# COMPUTE_CLUSTER0_CTL_CFG_PI register map
Vendor: Texas Instruments
Peripheral module from a debugger description file (folder J7VCL).
Registers are 32-bit, read-write, reset 0x0 unless marked. A register's access mark holds for its fields unless they carry their own. Offsets are as the file gives them; lines under a group give offsets from that group; [hi:lo] are bit positions; {n}, {i} and the like mark numbered series; 'fields as' and 'values as' point back to an identical list; <NAME> marks a mode.

## COMPUTE_CLUSTER0_CTL_CFG_PI (part 1 of 2)
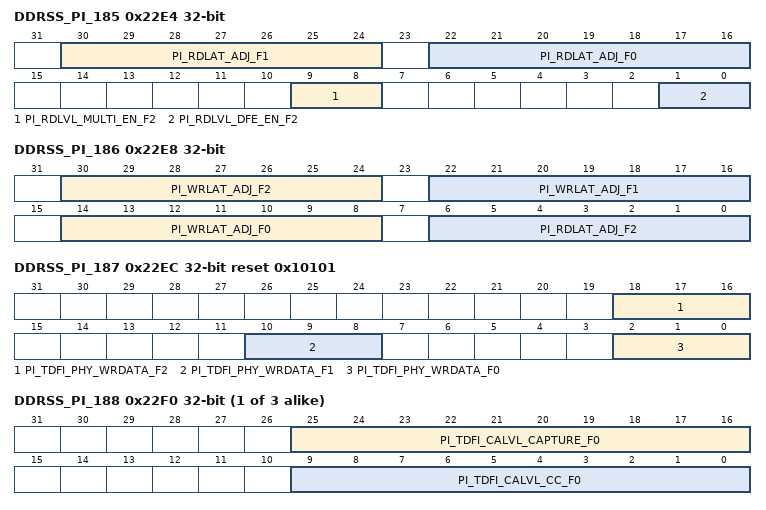
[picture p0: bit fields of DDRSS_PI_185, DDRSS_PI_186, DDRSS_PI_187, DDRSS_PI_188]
0x22E4 DDRSS_PI_185
  [30:24] PI_RDLAT_ADJ_F1 — Adjusts the relative timing between DFI read commands and the dfi_rddata_en signal for frequency set 1.
  [22:16] PI_RDLAT_ADJ_F0 — Adjusts the relative timing between DFI read commands and the dfi_rddata_en signal for frequency set 0.
  [9:8] PI_RDLVL_MULTI_EN_F2 — Enable Multi-pattern (from PI_RDLVL_PATTERN_START, total PI_RDLVL_PATTERN_NUM) for read training for frequency set 2.
  [1:0] PI_RDLVL_DFE_EN_F2 — Enable DFE (PATTERN 8,9) for read training for frequency set 2.
0x22E8 DDRSS_PI_186
  [30:24] PI_WRLAT_ADJ_F2 — Adjusts the relative timing in memory clocks between DFI write commands and the dfi_wrdata_en signal for frequency set 2.
  [22:16] PI_WRLAT_ADJ_F1 — Adjusts the relative timing in memory clocks between DFI write commands and the dfi_wrdata_en signal for frequency set 1.
  [14:8] PI_WRLAT_ADJ_F0 — Adjusts the relative timing in memory clocks between DFI write commands and the dfi_wrdata_en signal for frequency set 0.
  [6:0] PI_RDLAT_ADJ_F2 — Adjusts the relative timing between DFI read commands and the dfi_rddata_en signal for frequency set 2.
0x22EC DDRSS_PI_187 reset 0x10101
  [18:16] PI_TDFI_PHY_WRDATA_F2 — Defines the DFI tPHY_WRDATA timing parameter (in DFI PHY clocks) for frequency set 2, the maximum cycles between a dfi_wrdata_en assertion and a dfi_wrdata signal.
  [10:8] PI_TDFI_PHY_WRDATA_F1 — Defines the DFI tPHY_WRDATA timing parameter (in DFI PHY clocks) for frequency set 1, the maximum cycles between a dfi_wrdata_en assertion and a dfi_wrdata signal.
  [2:0] PI_TDFI_PHY_WRDATA_F0 — Defines the DFI tPHY_WRDATA timing parameter (in DFI PHY clocks) for frequency set 0, the maximum cycles between a dfi_wrdata_en assertion and a dfi_wrdata signal.
{0x2000+4i} DDRSS_PI_{i} (i=188..190)
  [25:16] PI_TDFI_CALVL_CAPTURE_F{i-188} — Defines the DFI tCALVL_CAPTURE timing parameter (in DFI clocks) for frequency set {i-188}, the minimum cycles between a calibration command and a dfi_calvl_capture pulse.
  [9:0] PI_TDFI_CALVL_CC_F{i-188} — Defines the DFI tCALVL_CC timing parameter (in DFI clocks) for frequency set {i-188}, the minimum cycles between calibration commands.
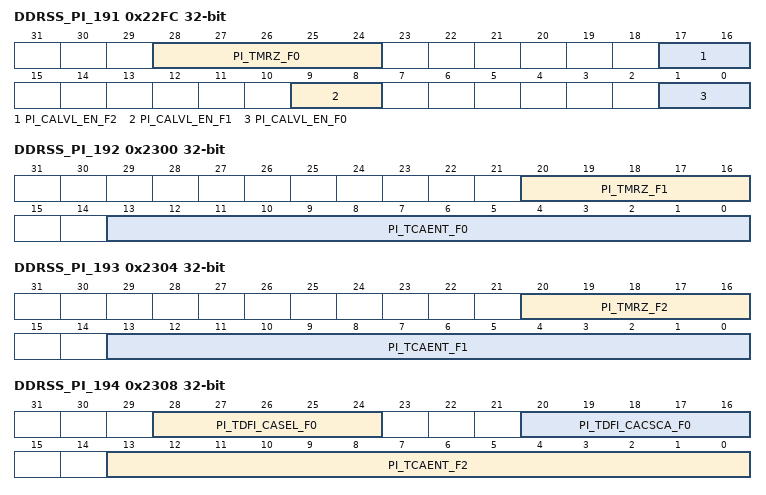
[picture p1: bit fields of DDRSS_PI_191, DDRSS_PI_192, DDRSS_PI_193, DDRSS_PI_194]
0x22FC DDRSS_PI_191
  [28:24] PI_TMRZ_F0 — Defines the delay between a MRW CA exit command and the DQ tristate in memory clocks for frequency set 0.
  [17:16] PI_CALVL_EN_F2 — Enable the PI CA training module.
  [9:8] PI_CALVL_EN_F1 — Enable the PI CA training module.
  [1:0] PI_CALVL_EN_F0 — Enable the PI CA training module.
0x2300 DDRSS_PI_192
  [20:16] PI_TMRZ_F1 — Defines the delay between a MRW CA exit command and the DQ tristate in memory clocks for frequency set 1.
  [13:0] PI_TCAENT_F0 — Defines the DRAM tCAENT term, in memory clocks for frequency set 0.
0x2304 DDRSS_PI_193
  [20:16] PI_TMRZ_F2 — Defines the delay between a MRW CA exit command and the DQ tristate in memory clocks for frequency set 2.
  [13:0] PI_TCAENT_F1 — Defines the DRAM tCAENT term, in memory clocks for frequency set 1.
0x2308 DDRSS_PI_194
  [28:24] PI_TDFI_CASEL_F0 — Defines the DFI tcalvl_ca_sel timing parameter, the width of dfi_calvl_ca_sel in PHY DFI clock cycles for frequency set 0.
  [20:16] PI_TDFI_CACSCA_F0 — Defines the DFI tcalvl_cs_ca timing parameter, the number of PHY DFI clocks from the assertion of dfi_calvl_ca_sel to the assertion of dfi_cs for frequency set 0.
  [13:0] PI_TCAENT_F2 — Defines the DRAM tCAENT term, in memory clocks for frequency set 2.
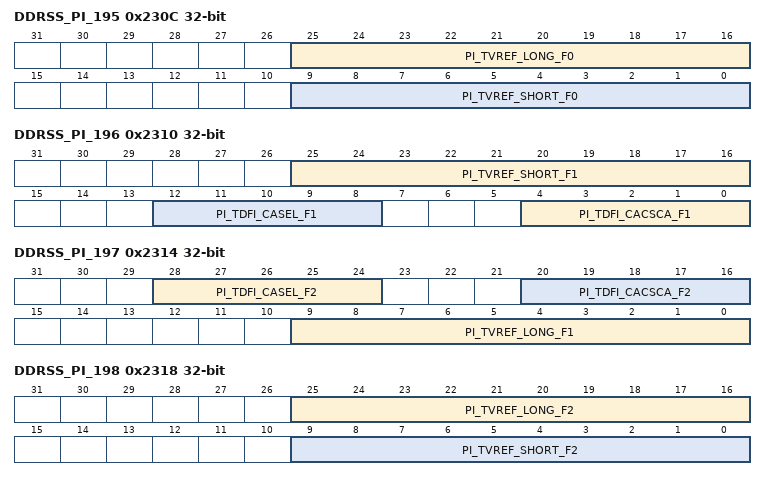
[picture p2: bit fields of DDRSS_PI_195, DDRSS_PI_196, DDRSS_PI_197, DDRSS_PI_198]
0x230C DDRSS_PI_195
  [25:16] PI_TVREF_LONG_F0 — Defines the delay in PI clock cycles between the dfi_calvl_strobe to the next command if the pi_calvl_vref_stepsize parameter gt 1 for frequency set 0.
  [9:0] PI_TVREF_SHORT_F0 — Defines the delay in PI clock cycles between the dfi_calvl_strobe to the next command if the pi_calvl_vref_stepsize parameter = 1 for frequency set 0.
0x2310 DDRSS_PI_196
  [25:16] PI_TVREF_SHORT_F1 — Defines the delay in PI clock cycles between the dfi_calvl_strobe to the next command if the pi_calvl_vref_stepsize parameter = 1 for frequency set 1.
  [12:8] PI_TDFI_CASEL_F1 — Defines the DFI tcalvl_ca_sel timing parameter, the width of dfi_calvl_ca_sel in PHY DFI clock cycles for frequency set 1.
  [4:0] PI_TDFI_CACSCA_F1 — Defines the DFI tcalvl_cs_ca timing parameter, the number of PHY DFI clocks from the assertion of dfi_calvl_ca_sel to the assertion of dfi_cs for frequency set 1.
0x2314 DDRSS_PI_197
  [28:24] PI_TDFI_CASEL_F2 — Defines the DFI tcalvl_ca_sel timing parameter, the width of dfi_calvl_ca_sel in PHY DFI clock cycles for frequency set 2.
  [20:16] PI_TDFI_CACSCA_F2 — Defines the DFI tcalvl_cs_ca timing parameter, the number of PHY DFI clocks from the assertion of dfi_calvl_ca_sel to the assertion of dfi_cs for frequency set 2.
  [9:0] PI_TVREF_LONG_F1 — Defines the delay in PI clock cycles between the dfi_calvl_strobe to the next command if the pi_calvl_vref_stepsize parameter gt 1 for frequency set 1.
0x2318 DDRSS_PI_198
  [25:16] PI_TVREF_LONG_F2 — Defines the delay in PI clock cycles between the dfi_calvl_strobe to the next command if the pi_calvl_vref_stepsize parameter gt 1 for frequency set 2.
  [9:0] PI_TVREF_SHORT_F2 — Defines the delay in PI clock cycles between the dfi_calvl_strobe to the next command if the pi_calvl_vref_stepsize parameter = 1 for frequency set 2.
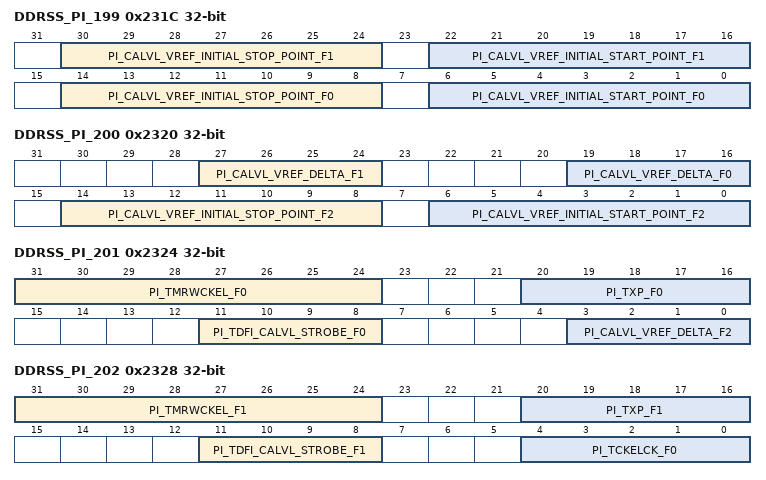
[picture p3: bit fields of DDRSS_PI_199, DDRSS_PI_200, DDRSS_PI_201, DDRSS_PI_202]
0x231C DDRSS_PI_199
  [30:24] PI_CALVL_VREF_INITIAL_STOP_POINT_F1 — The end point of initial training for the Vref(ca) training for frequency set 1 { vrefca_range, vref_ca_setting
  [22:16] PI_CALVL_VREF_INITIAL_START_POINT_F1 — The start point of initial training for the Vref(ca) training for frequency set 1 { vrefca_range, vref_ca_setting
  [14:8] PI_CALVL_VREF_INITIAL_STOP_POINT_F0 — The end point of initial training for the Vref(ca) training for frequency set 0 { vrefca_range, vref_ca_setting
  [6:0] PI_CALVL_VREF_INITIAL_START_POINT_F0 — The start point of initial training for the Vref(ca) training for frequency set 0 { vrefca_range, vref_ca_setting
0x2320 DDRSS_PI_200
  [27:24] PI_CALVL_VREF_DELTA_F1 — The delta fro the current CA vref for non-initial CA training for frequency set 1.
  [19:16] PI_CALVL_VREF_DELTA_F0 — The delta fro the current CA vref for non-initial CA training for frequency set 0.
  [14:8] PI_CALVL_VREF_INITIAL_STOP_POINT_F2 — The end point of initial training for the Vref(ca) training for frequency set 2 { vrefca_range, vref_ca_setting
  [6:0] PI_CALVL_VREF_INITIAL_START_POINT_F2 — The start point of initial training for the Vref(ca) training for frequency set 2 { vrefca_range, vref_ca_setting
0x2324 DDRSS_PI_201
  [31:24] PI_TMRWCKEL_F0 — Valid Clock and CS Requirement before CKE deassert after MRW Command for frequency set 0.
  [20:16] PI_TXP_F0 — CKE assert to next valid command delay for frequency set 0.
  [11:8] PI_TDFI_CALVL_STROBE_F0 — Minimum number of DFI PHY clocks from dfi_calvl_data to dfi_calvl_strobe mode for frequency set 0.
  [3:0] PI_CALVL_VREF_DELTA_F2 — The delta fro the current CA vref for non-initial CA training for frequency set 2.
0x2328 DDRSS_PI_202
  [31:24] PI_TMRWCKEL_F1 — Valid Clock and CS Requirement before CKE deassert after MRW Command for frequency set 1.
  [20:16] PI_TXP_F1 — CKE assert to next valid command delay for frequency set 1.
  [11:8] PI_TDFI_CALVL_STROBE_F1 — Minimum number of DFI PHY clocks from dfi_calvl_data to dfi_calvl_strobe mode for frequency set 1.
  [4:0] PI_TCKELCK_F0 — Valid Clock Requirement after CKE deassert for frequency set 0.
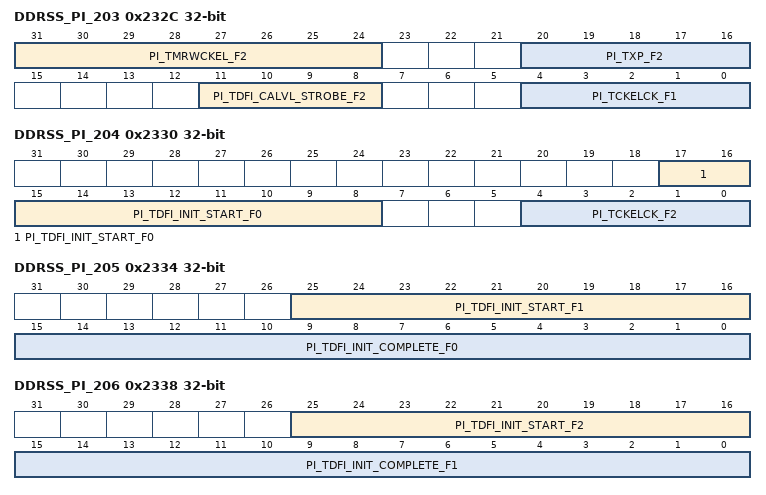
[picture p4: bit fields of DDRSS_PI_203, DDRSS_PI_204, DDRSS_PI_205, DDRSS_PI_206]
0x232C DDRSS_PI_203
  [31:24] PI_TMRWCKEL_F2 — Valid Clock and CS Requirement before CKE deassert after MRW Command for frequency set 2.
  [20:16] PI_TXP_F2 — CKE assert to next valid command delay for frequency set 2.
  [11:8] PI_TDFI_CALVL_STROBE_F2 — Minimum number of DFI PHY clocks from dfi_calvl_data to dfi_calvl_strobe mode for frequency set 2.
  [4:0] PI_TCKELCK_F1 — Valid Clock Requirement after CKE deassert for frequency set 1.
0x2330 DDRSS_PI_204
  [17:8] PI_TDFI_INIT_START_F0 — Defines the DFI tINIT_START timing parameter (in DFI clocks) for frequency set 0, the maximum number of cycles between a dfi_init_start assertion and a dfi_init_complete de-assertion from the PHY.
  [4:0] PI_TCKELCK_F2 — Valid Clock Requirement after CKE deassert for frequency set 2.
0x2334 DDRSS_PI_205
  [25:16] PI_TDFI_INIT_START_F1 — Defines the DFI tINIT_START timing parameter (in DFI clocks) for frequency set 1, the maximum number of cycles between a dfi_init_start assertion and a dfi_init_complete de-assertion from the PHY.
  [15:0] PI_TDFI_INIT_COMPLETE_F0 — Defines the DFI tINIT_COMPLETE timing parameter (in DFI clocks) for frequency set 0, the maximum cycles between a dfi_init_start de-assertion and a dfi_init_complete assertion from the PHY.
0x2338 DDRSS_PI_206
  [25:16] PI_TDFI_INIT_START_F2 — Defines the DFI tINIT_START timing parameter (in DFI clocks) for frequency set 2, the maximum number of cycles between a dfi_init_start assertion and a dfi_init_complete de-assertion from the PHY.
  [15:0] PI_TDFI_INIT_COMPLETE_F1 — Defines the DFI tINIT_COMPLETE timing parameter (in DFI clocks) for frequency set 1, the maximum cycles between a dfi_init_start de-assertion and a dfi_init_complete assertion from the PHY.
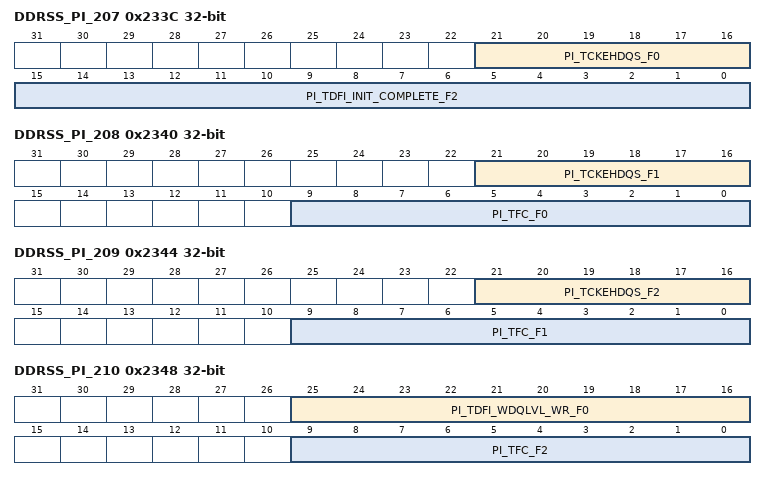
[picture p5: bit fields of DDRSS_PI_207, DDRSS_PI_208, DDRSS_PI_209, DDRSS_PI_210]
0x233C DDRSS_PI_207
  [21:16] PI_TCKEHDQS_F0 — The DRAM timing tCKEHDQS, minimum delay from CKE high to strobe high impedance for frequency set 0.
  [15:0] PI_TDFI_INIT_COMPLETE_F2 — Defines the DFI tINIT_COMPLETE timing parameter (in DFI clocks) for frequency set 2, the maximum cycles between a dfi_init_start de-assertion and a dfi_init_complete assertion from the PHY.
0x2340 DDRSS_PI_208
  [21:16] PI_TCKEHDQS_F1 — The DRAM timing tCKEHDQS, minimum delay from CKE high to strobe high impedance for frequency set 1.
  [9:0] PI_TFC_F0 — The delay in PHY clock cycles from setting MR13.OP7 to any valid command for frequency set 0.
0x2344 DDRSS_PI_209
  [21:16] PI_TCKEHDQS_F2 — The DRAM timing tCKEHDQS, minimum delay from CKE high to strobe high impedance for frequency set 2.
  [9:0] PI_TFC_F1 — The delay in PHY clock cycles from setting MR13.OP7 to any valid command for frequency set 1.
0x2348 DDRSS_PI_210
  [25:16] PI_TDFI_WDQLVL_WR_F0 — Switch time from write to read for frequency set 0.
  [9:0] PI_TFC_F2 — The delay in PHY clock cycles from setting MR13.OP7 to any valid command for frequency set 2.
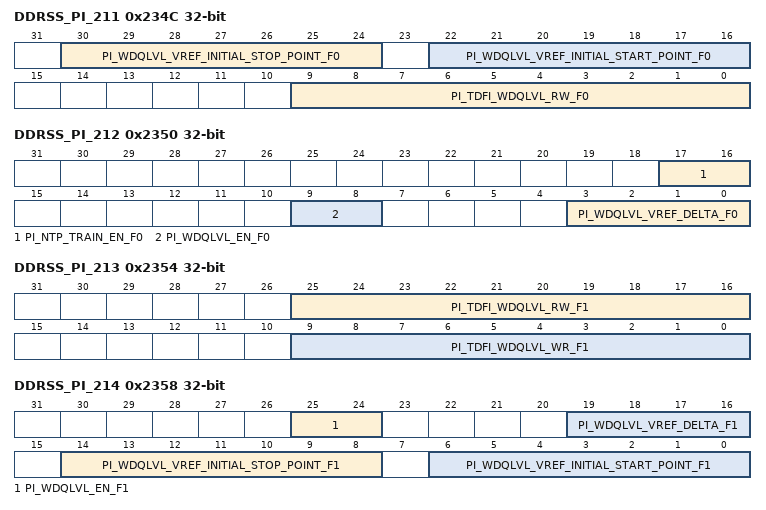
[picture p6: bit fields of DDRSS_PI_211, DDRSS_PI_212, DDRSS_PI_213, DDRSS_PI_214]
0x234C DDRSS_PI_211
  [30:24] PI_WDQLVL_VREF_INITIAL_STOP_POINT_F0 — Write DQ training vref initial training stop value for frequency set 0.
  [22:16] PI_WDQLVL_VREF_INITIAL_START_POINT_F0 — Write DQ training vref initial training start value for frequency set 0.
  [9:0] PI_TDFI_WDQLVL_RW_F0 — Switch time from read to write for frequency set 0.
0x2350 DDRSS_PI_212
  [17:16] PI_NTP_TRAIN_EN_F0 — Indicates whether the no topology WDQ training is enabled.
  [9:8] PI_WDQLVL_EN_F0 — Indicates if Write DQ leveling is enabled for frequency set 0.
  [3:0] PI_WDQLVL_VREF_DELTA_F0 — The delta from the current Write DQ vref adjustment for non-initial wdq training for frequency set 0.
0x2354 DDRSS_PI_213
  [25:16] PI_TDFI_WDQLVL_RW_F1 — Switch time from read to write for frequency set 1.
  [9:0] PI_TDFI_WDQLVL_WR_F1 — Switch time from write to read for frequency set 1.
0x2358 DDRSS_PI_214
  [25:24] PI_WDQLVL_EN_F1 — Indicates if Write DQ leveling is enabled for frequency set 1.
  [19:16] PI_WDQLVL_VREF_DELTA_F1 — The delta from the current Write DQ vref adjustment for non-initial wdq training for frequency set 1.
  [14:8] PI_WDQLVL_VREF_INITIAL_STOP_POINT_F1 — Write DQ training vref initial training stop value for frequency set 1.
  [6:0] PI_WDQLVL_VREF_INITIAL_START_POINT_F1 — Write DQ training vref initial training start value for frequency set 1.
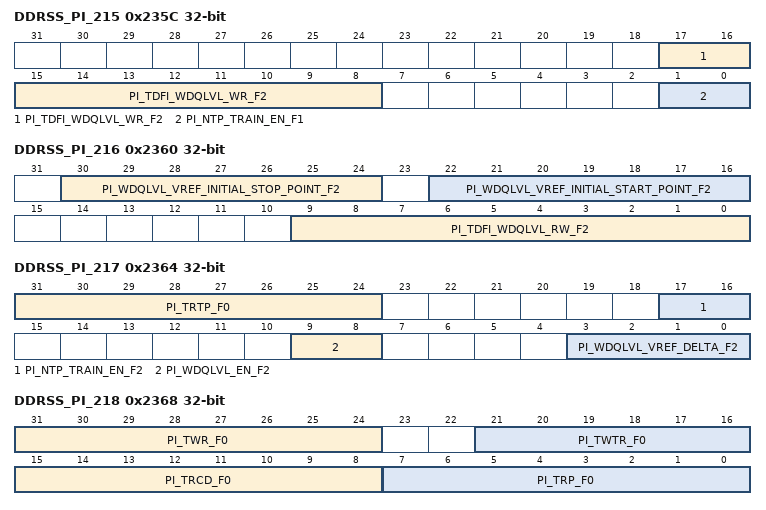
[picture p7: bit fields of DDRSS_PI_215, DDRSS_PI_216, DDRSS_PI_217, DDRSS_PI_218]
0x235C DDRSS_PI_215
  [17:8] PI_TDFI_WDQLVL_WR_F2 — Switch time from write to read for frequency set 2.
  [1:0] PI_NTP_TRAIN_EN_F1 — Indicates whether the no topology WDQ training is enabled.
0x2360 DDRSS_PI_216
  [30:24] PI_WDQLVL_VREF_INITIAL_STOP_POINT_F2 — Write DQ training vref initial training stop value for frequency set 2.
  [22:16] PI_WDQLVL_VREF_INITIAL_START_POINT_F2 — Write DQ training vref initial training start value for frequency set 2.
  [9:0] PI_TDFI_WDQLVL_RW_F2 — Switch time from read to write for frequency set 2.
0x2364 DDRSS_PI_217
  [31:24] PI_TRTP_F0 — DRAM tRTP value in cycles for frequency set 0.
  [17:16] PI_NTP_TRAIN_EN_F2 — Indicates whether the no topology WDQ training is enabled.
  [9:8] PI_WDQLVL_EN_F2 — Indicates if Write DQ leveling is enabled for frequency set 2.
  [3:0] PI_WDQLVL_VREF_DELTA_F2 — The delta from the current Write DQ vref adjustment for non-initial wdq training for frequency set 2.
0x2368 DDRSS_PI_218
  [31:24] PI_TWR_F0 — DRAM tWR value in cycles for frequency set 0.
  [21:16] PI_TWTR_F0 — DRAM tWTR value in cycles for frequency set 0.
  [15:8] PI_TRCD_F0 — DRAM tRCD value in cycles for frequency set 0.
  [7:0] PI_TRP_F0 — DRAM tRP value in cycles for frequency set 0.
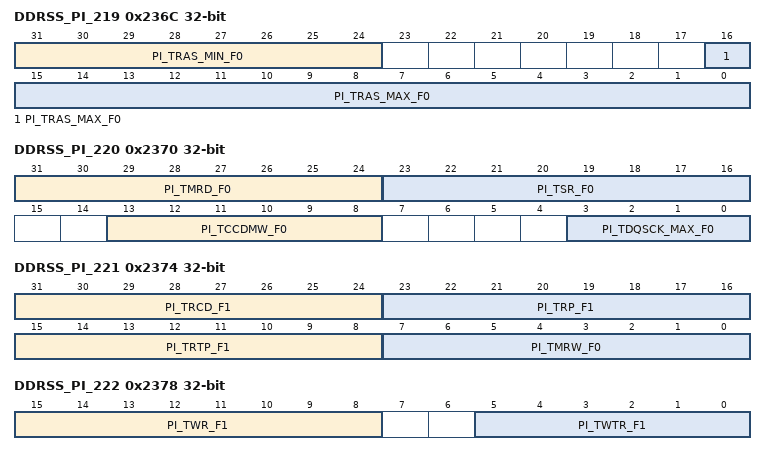
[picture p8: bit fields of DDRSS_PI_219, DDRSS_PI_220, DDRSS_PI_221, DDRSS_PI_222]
0x236C DDRSS_PI_219
  [31:24] PI_TRAS_MIN_F0 — DRAM tRAS_MIN value in cycles for frequency set 0.
  [16:0] PI_TRAS_MAX_F0 — DRAM tRAS_MAX value in cycles for frequency set 0.
0x2370 DDRSS_PI_220
  [31:24] PI_TMRD_F0 — DRAM tMRD value in cycles for frequency set 0.
  [23:16] PI_TSR_F0 — Min cycles from sref entry to sref exit for frequency set 0.
  [13:8] PI_TCCDMW_F0 — LPDDR4 DRAM tCCDMW in cycles for frequency set 0.
  [3:0] PI_TDQSCK_MAX_F0 — Additional delay needed for tDQSCK for frequency set 0.
0x2374 DDRSS_PI_221
  [31:24] PI_TRCD_F1 — DRAM tRCD value in cycles for frequency set 1.
  [23:16] PI_TRP_F1 — DRAM tRP value in cycles for frequency set 1.
  [15:8] PI_TRTP_F1 — DRAM tRTP value in cycles for frequency set 1.
  [7:0] PI_TMRW_F0 — DRAM tMRW value in cycles for frequency set 0.
0x2378 DDRSS_PI_222
  [15:8] PI_TWR_F1 — DRAM tWR value in cycles for frequency set 1.
  [5:0] PI_TWTR_F1 — DRAM tWTR value in cycles for frequency set 1.
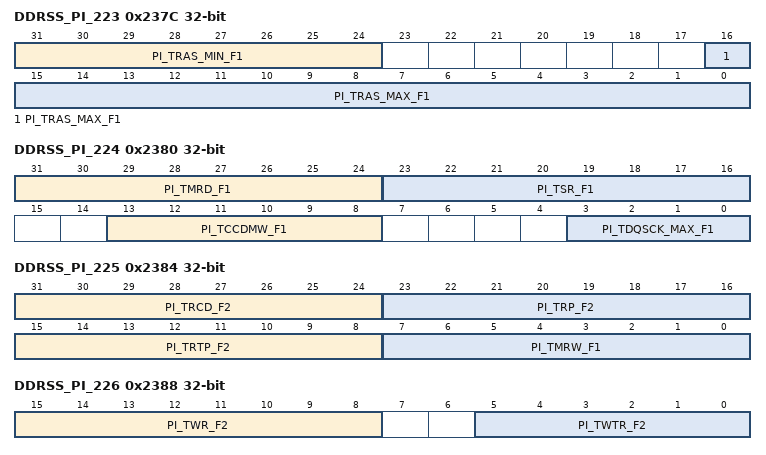
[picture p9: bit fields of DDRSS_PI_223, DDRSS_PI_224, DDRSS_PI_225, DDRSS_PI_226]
0x237C DDRSS_PI_223
  [31:24] PI_TRAS_MIN_F1 — DRAM tRAS_MIN value in cycles for frequency set 1.
  [16:0] PI_TRAS_MAX_F1 — DRAM tRAS_MAX value in cycles for frequency set 1.
0x2380 DDRSS_PI_224
  [31:24] PI_TMRD_F1 — DRAM tMRD value in cycles for frequency set 1.
  [23:16] PI_TSR_F1 — Min cycles from sref entry to sref exit for frequency set 1.
  [13:8] PI_TCCDMW_F1 — LPDDR4 DRAM tCCDMW in cycles for frequency set 1.
  [3:0] PI_TDQSCK_MAX_F1 — Additional delay needed for tDQSCK for frequency set 1.
0x2384 DDRSS_PI_225
  [31:24] PI_TRCD_F2 — DRAM tRCD value in cycles for frequency set 2.
  [23:16] PI_TRP_F2 — DRAM tRP value in cycles for frequency set 2.
  [15:8] PI_TRTP_F2 — DRAM tRTP value in cycles for frequency set 2.
  [7:0] PI_TMRW_F1 — DRAM tMRW value in cycles for frequency set 1.
0x2388 DDRSS_PI_226
  [15:8] PI_TWR_F2 — DRAM tWR value in cycles for frequency set 2.
  [5:0] PI_TWTR_F2 — DRAM tWTR value in cycles for frequency set 2.
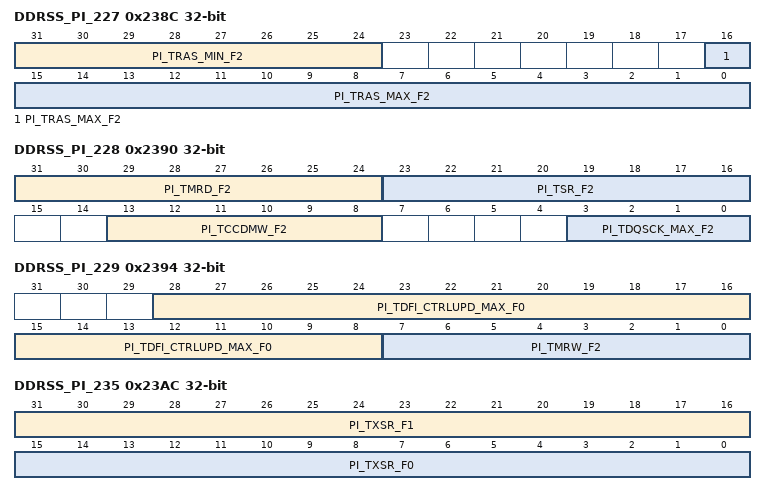
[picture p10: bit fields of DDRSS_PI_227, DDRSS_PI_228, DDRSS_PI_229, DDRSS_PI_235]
0x238C DDRSS_PI_227
  [31:24] PI_TRAS_MIN_F2 — DRAM tRAS_MIN value in cycles for frequency set 2.
  [16:0] PI_TRAS_MAX_F2 — DRAM tRAS_MAX value in cycles for frequency set 2.
0x2390 DDRSS_PI_228
  [31:24] PI_TMRD_F2 — DRAM tMRD value in cycles for frequency set 2.
  [23:16] PI_TSR_F2 — Min cycles from sref entry to sref exit for frequency set 2.
  [13:8] PI_TCCDMW_F2 — LPDDR4 DRAM tCCDMW in cycles for frequency set 2.
  [3:0] PI_TDQSCK_MAX_F2 — Additional delay needed for tDQSCK for frequency set 2.
0x2394 DDRSS_PI_229
  [28:8] PI_TDFI_CTRLUPD_MAX_F0 — Defines the DFI tCTRLUPD_MAX timing parameter (in DFI clocks) for frequency set 0, the maximum cycles that dfi_ctrlupd_req can be asserted.
  [7:0] PI_TMRW_F2 — DRAM tMRW value in cycles for frequency set 2.
0x2398 DDRSS_PI_230
  [31:0] PI_TDFI_CTRLUPD_INTERVAL_F0 — Defines the DFI tCTRLUPD_INTERVAL timing parameter (in DFI clocks) for frequency set 0, the maximum cycles between dfi_ctrlupd_req assertions.
0x239C DDRSS_PI_231
  [20:0] PI_TDFI_CTRLUPD_MAX_F1 — Defines the DFI tCTRLUPD_MAX timing parameter (in DFI clocks) for frequency set 1, the maximum cycles that dfi_ctrlupd_req can be asserted.
0x23A0 DDRSS_PI_232
  [31:0] PI_TDFI_CTRLUPD_INTERVAL_F1 — Defines the DFI tCTRLUPD_INTERVAL timing parameter (in DFI clocks) for frequency set 1, the maximum cycles between dfi_ctrlupd_req assertions.
0x23A4 DDRSS_PI_233
  [20:0] PI_TDFI_CTRLUPD_MAX_F2 — Defines the DFI tCTRLUPD_MAX timing parameter (in DFI clocks) for frequency set 2, the maximum cycles that dfi_ctrlupd_req can be asserted.
0x23A8 DDRSS_PI_234
  [31:0] PI_TDFI_CTRLUPD_INTERVAL_F2 — Defines the DFI tCTRLUPD_INTERVAL timing parameter (in DFI clocks) for frequency set 2, the maximum cycles between dfi_ctrlupd_req assertions.
0x23AC DDRSS_PI_235
  [31:16] PI_TXSR_F1 — DRAM TXSR value for frequency set 1 in cycles.
  [15:0] PI_TXSR_F0 — DRAM TXSR value for frequency set 0 in cycles.
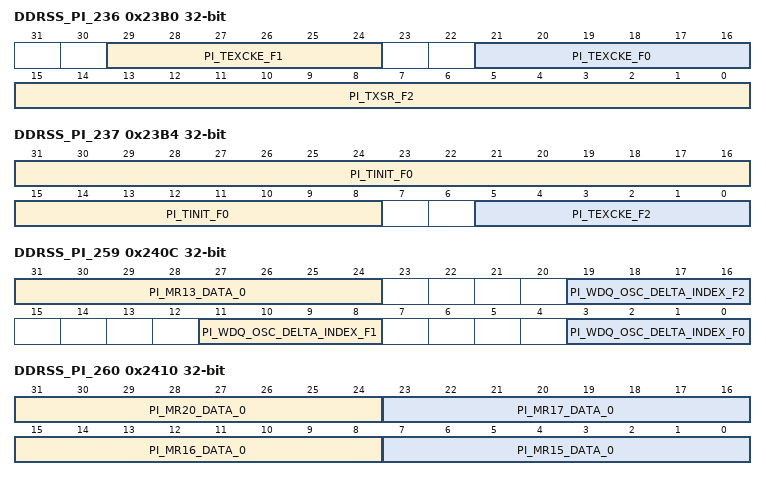
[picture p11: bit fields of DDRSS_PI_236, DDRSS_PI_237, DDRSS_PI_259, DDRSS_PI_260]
0x23B0 DDRSS_PI_236
  [29:24] PI_TEXCKE_F1 — DRAM CKE low after SREF command timing for frequency set 1.
  [21:16] PI_TEXCKE_F0 — DRAM CKE low after SREF command timing for frequency set 0.
  [15:0] PI_TXSR_F2 — DRAM TXSR value for frequency set 2 in cycles.
0x23B4 DDRSS_PI_237
  [31:8] PI_TINIT_F0 — DRAM tINIT value for frequency set 0 in cycles.
  [5:0] PI_TEXCKE_F2 — DRAM CKE low after SREF command timing for frequency set 2.
{0x2000+4i} DDRSS_PI_{i} (i=238..240)
  [23:0] PI_TINIT{i-235}_F0 — DRAM tINIT{i-235} value for frequency set 0 in cycles.
0x23C4 DDRSS_PI_241
  [15:0] PI_TXSNR_F0 — DRAM tXSNR value for frequency set 0 in cycles.
0x23C8 DDRSS_PI_242
  [23:0] PI_TINIT_F1 — DRAM tINIT value for frequency set 1 in cycles.
{0x2000+4i} DDRSS_PI_{i} (i=243..245)
  [23:0] PI_TINIT{i-240}_F1 — DRAM tINIT{i-240} value for frequency set 1 in cycles.
0x23D8 DDRSS_PI_246
  [15:0] PI_TXSNR_F1 — DRAM tXSNR value for frequency set 1 in cycles.
0x23DC DDRSS_PI_247
  [23:0] PI_TINIT_F2 — DRAM tINIT value for frequency set 2 in cycles.
{0x2000+4i} DDRSS_PI_{i} (i=248..250)
  [23:0] PI_TINIT{i-245}_F2 — DRAM tINIT{i-245} value for frequency set 2 in cycles.
0x23EC DDRSS_PI_251
  [15:0] PI_TXSNR_F2 — DRAM tXSNR value for frequency set 2 in cycles.
0x23F0 DDRSS_PI_252
  [27:16] PI_TZQCAL_F0 — Holds the DRAM ZQCAL value for frequency set 0 in cycles.
0x23F4 DDRSS_PI_253
  [6:0] PI_TZQLAT_F0 — Holds the DRAM ZQLAT value for frequency set 0 in cycles.
0x23F8 DDRSS_PI_254
  [27:16] PI_TZQCAL_F1 — Holds the DRAM ZQCAL value for frequency set 1 in cycles.
0x23FC DDRSS_PI_255
  [6:0] PI_TZQLAT_F1 — Holds the DRAM ZQLAT value for frequency set 1 in cycles.
0x2400 DDRSS_PI_256
  [27:16] PI_TZQCAL_F2 — Holds the DRAM ZQCAL value for frequency set 2 in cycles.
0x2404 DDRSS_PI_257
  [6:0] PI_TZQLAT_F2 — Holds the DRAM ZQLAT value for frequency set 2 in cycles.
0x2408 DDRSS_PI_258 (reset mask 0xFFF0FFF)
0x240C DDRSS_PI_259
  [31:24] PI_MR13_DATA_0 — Data to program into memory mode register 13 for chip select 0.
  [19:16] PI_WDQ_OSC_DELTA_INDEX_F2 — WDQ DQS delay delta index for OSC triggered periodic training for frequency set 2.
  [11:8] PI_WDQ_OSC_DELTA_INDEX_F1 — WDQ DQS delay delta index for OSC triggered periodic training for frequency set 1.
  [3:0] PI_WDQ_OSC_DELTA_INDEX_F0 — WDQ DQS delay delta index for OSC triggered periodic training for frequency set 0.
0x2410 DDRSS_PI_260
  [31:24] PI_MR20_DATA_0 — Data to program into memory mode register 20 for chip select 0.
  [23:16] PI_MR17_DATA_0 — Data to program into memory mode register 17 for chip select 0.
  [15:8] PI_MR16_DATA_0 — Data to program into memory mode register 16 for chip select 0.
  [7:0] PI_MR15_DATA_0 — Data to program into memory mode register 15 for chip select 0.
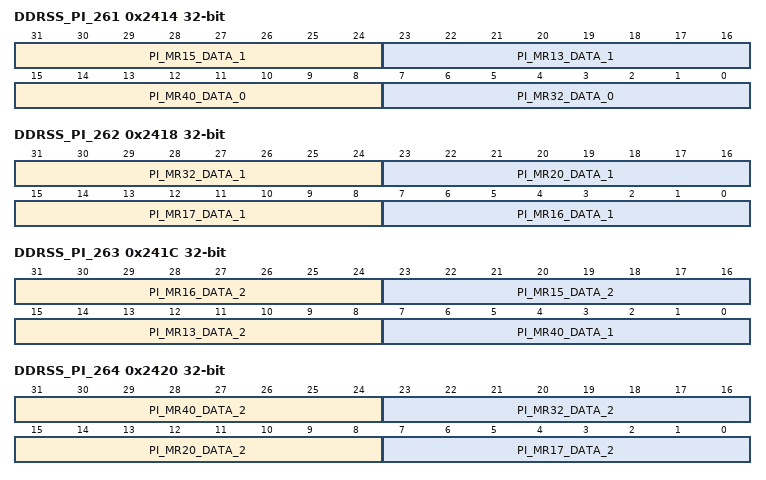
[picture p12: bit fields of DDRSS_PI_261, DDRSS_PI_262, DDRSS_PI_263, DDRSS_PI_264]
0x2414 DDRSS_PI_261
  [31:24] PI_MR15_DATA_1 — Data to program into memory mode register 15 for chip select 1.
  [23:16] PI_MR13_DATA_1 — Data to program into memory mode register 13 for chip select 1.
  [15:8] PI_MR40_DATA_0 — Data to program into memory mode register 40 for chip select 0.
  [7:0] PI_MR32_DATA_0 — Data to program into memory mode register 32 for chip select 0.
0x2418 DDRSS_PI_262
  [31:24] PI_MR32_DATA_1 — Data to program into memory mode register 32 for chip select 1.
  [23:16] PI_MR20_DATA_1 — Data to program into memory mode register 20 for chip select 1.
  [15:8] PI_MR17_DATA_1 — Data to program into memory mode register 17 for chip select 1.
  [7:0] PI_MR16_DATA_1 — Data to program into memory mode register 16 for chip select 1.
0x241C DDRSS_PI_263
  [31:24] PI_MR16_DATA_2 — Data to program into memory mode register 16 for chip select 2.
  [23:16] PI_MR15_DATA_2 — Data to program into memory mode register 15 for chip select 2.
  [15:8] PI_MR13_DATA_2 — Data to program into memory mode register 13 for chip select 2.
  [7:0] PI_MR40_DATA_1 — Data to program into memory mode register 40 for chip select 1.
0x2420 DDRSS_PI_264
  [31:24] PI_MR40_DATA_2 — Data to program into memory mode register 40 for chip select 2.
  [23:16] PI_MR32_DATA_2 — Data to program into memory mode register 32 for chip select 2.
  [15:8] PI_MR20_DATA_2 — Data to program into memory mode register 20 for chip select 2.
  [7:0] PI_MR17_DATA_2 — Data to program into memory mode register 17 for chip select 2.
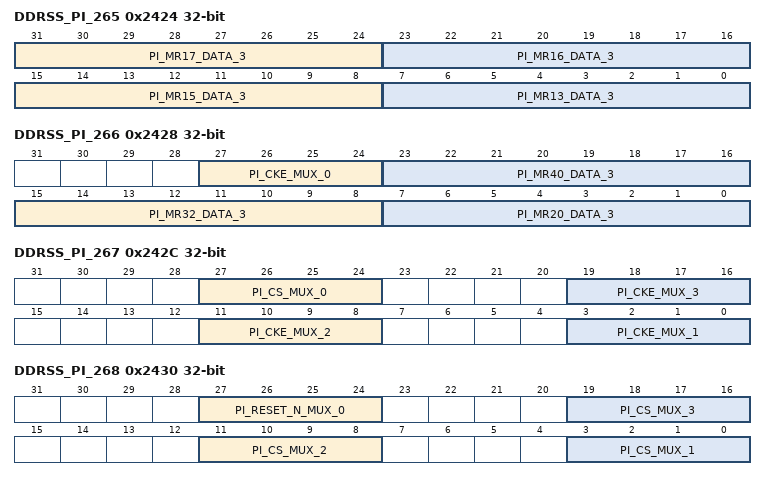
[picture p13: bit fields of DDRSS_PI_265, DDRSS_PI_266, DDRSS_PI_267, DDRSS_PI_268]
0x2424 DDRSS_PI_265
  [31:24] PI_MR17_DATA_3 — Data to program into memory mode register 17 for chip select 3.
  [23:16] PI_MR16_DATA_3 — Data to program into memory mode register 16 for chip select 3.
  [15:8] PI_MR15_DATA_3 — Data to program into memory mode register 15 for chip select 3.
  [7:0] PI_MR13_DATA_3 — Data to program into memory mode register 13 for chip select 3.
0x2428 DDRSS_PI_266
  [27:24] PI_CKE_MUX_0 — Command pin CKE_0 mux selector
  [23:16] PI_MR40_DATA_3 — Data to program into memory mode register 40 for chip select 3.
  [15:8] PI_MR32_DATA_3 — Data to program into memory mode register 32 for chip select 3.
  [7:0] PI_MR20_DATA_3 — Data to program into memory mode register 20 for chip select 3.
0x242C DDRSS_PI_267
  [27:24] PI_CS_MUX_0 — Command pin CS_0 mux selector
  [19:16] PI_CKE_MUX_3 — Command pin CKE_3 mux selector
  [11:8] PI_CKE_MUX_2 — Command pin CKE_2 mux selector
  [3:0] PI_CKE_MUX_1 — Command pin CKE_1 mux selector
0x2430 DDRSS_PI_268
  [27:24] PI_RESET_N_MUX_0 — Command pin RESET_N_0 mux selector
  [19:16] PI_CS_MUX_3 — Command pin CS_3 mux selector
  [11:8] PI_CS_MUX_2 — Command pin CS_2 mux selector
  [3:0] PI_CS_MUX_1 — Command pin CS_1 mux selector
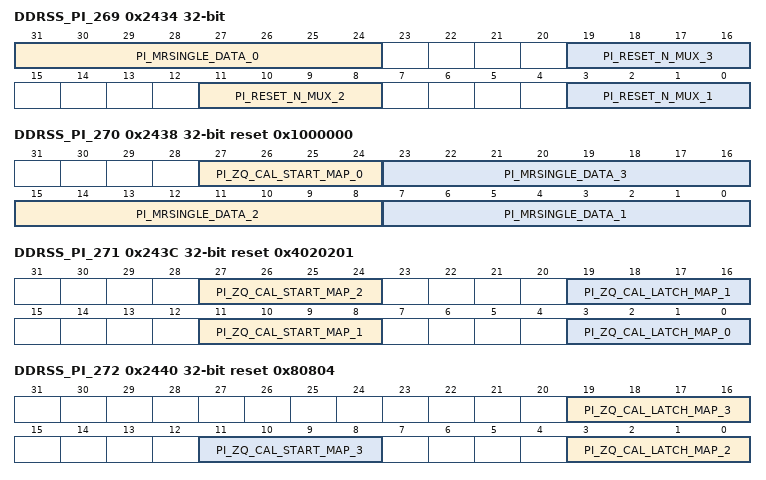
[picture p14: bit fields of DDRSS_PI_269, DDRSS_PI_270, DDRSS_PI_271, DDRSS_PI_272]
0x2434 DDRSS_PI_269
  [31:24] PI_MRSINGLE_DATA_0 — Data to program into memory mode register single write to chip select 0.
  [19:16] PI_RESET_N_MUX_3 — Command pin RESET_N_3 mux selector
  [11:8] PI_RESET_N_MUX_2 — Command pin RESET_N_2 mux selector
  [3:0] PI_RESET_N_MUX_1 — Command pin RESET_N_1 mux selector
0x2438 DDRSS_PI_270 reset 0x1000000
  [27:24] PI_ZQ_CAL_START_MAP_0 — Defines which chip select(s) will receive ZQ calibration start commands simultaneously on iteration 0 of the ZQ START initialization and periodic command sequences.
  [23:16] PI_MRSINGLE_DATA_3 — Data to program into memory mode register single write to chip select 3.
  [15:8] PI_MRSINGLE_DATA_2 — Data to program into memory mode register single write to chip select 2.
  [7:0] PI_MRSINGLE_DATA_1 — Data to program into memory mode register single write to chip select 1.
0x243C DDRSS_PI_271 reset 0x4020201
  [27:24] PI_ZQ_CAL_START_MAP_2 — Defines which chip select(s) will receive ZQ calibration start commands simultaneously on iteration 2 of the ZQ START initialization and periodic command sequences.
  [19:16] PI_ZQ_CAL_LATCH_MAP_1 — Defines which chip select(s) will receive ZQ calibration latch commands simultaneously on iteration 1 of the ZQ LATCH initialization and periodic command sequences.
  [11:8] PI_ZQ_CAL_START_MAP_1 — Defines which chip select(s) will receive ZQ calibration start commands simultaneously on iteration 1 of the ZQ START initialization and periodic command sequences.
  [3:0] PI_ZQ_CAL_LATCH_MAP_0 — Defines which chip select(s) will receive ZQ calibration latch commands simultaneously on iteration 0 of the ZQ LATCH initialization and periodic command sequences.
0x2440 DDRSS_PI_272 reset 0x80804
  [19:16] PI_ZQ_CAL_LATCH_MAP_3 — Defines which chip select(s) will receive ZQ calibration latch commands simultaneously on iteration 3 of the ZQ LATCH initialization and periodic command sequences.
  [11:8] PI_ZQ_CAL_START_MAP_3 — Defines which chip select(s) will receive ZQ calibration start commands simultaneously on iteration 3 of the ZQ START initialization and periodic command sequences.
  [3:0] PI_ZQ_CAL_LATCH_MAP_2 — Defines which chip select(s) will receive ZQ calibration latch commands simultaneously on iteration 2 of the ZQ LATCH initialization and periodic command sequences.
0x2444 DDRSS_PI_273
  [31:16] PI_DQS_OSC_BASE_VALUE_1_0 — Base value for comparison of oscillator measurement for device 1 of rank 0
  [15:0] PI_DQS_OSC_BASE_VALUE_0_0 — Base value for comparison of oscillator measurement for device 0 of rank 0
0x2448 DDRSS_PI_274
  [31:16] PI_DQS_OSC_BASE_VALUE_1_1 — Base value for comparison of oscillator measurement for device 1 of rank 1
  [15:0] PI_DQS_OSC_BASE_VALUE_0_1 — Base value for comparison of oscillator measurement for device 0 of rank 1
0x244C DDRSS_PI_275
  [31:24] PI_MR11_DATA_F0_0 — Data to program into memory mode register 11 for chip select 0 for frequency set 0.
  [23:16] PI_MR3_DATA_F0_0 — Data to program into memory mode register 3 for chip select 0 for frequency set 0.
  [15:8] PI_MR2_DATA_F0_0 — Data to program into memory mode register 2 for chip select 0 for frequency set 0.
  [7:0] PI_MR1_DATA_F0_0 — Data to program into memory mode register 1 for chip select 0 for frequency set 0.
0x2450 DDRSS_PI_276
  [31:24] PI_MR23_DATA_F0_0 — Data to program into memory mode register 23 for chip select 0 for frequency set 0.
  [23:16] PI_MR22_DATA_F0_0 — Data to program into memory mode register 22 for chip select 0 for frequency set 0.
  [15:8] PI_MR14_DATA_F0_0 — Data to program into memory mode register 14 for chip select 0 for frequency set 0.
  [7:0] PI_MR12_DATA_F0_0 — Data to program into memory mode register 12 for chip select 0 for frequency set 0.
0x2454 DDRSS_PI_277
  [31:24] PI_MR11_DATA_F1_0 — Data to program into memory mode register 11 for chip select 0 for frequency set 1.
  [23:16] PI_MR3_DATA_F1_0 — Data to program into memory mode register 3 for chip select 0 for frequency set 1.
  [15:8] PI_MR2_DATA_F1_0 — Data to program into memory mode register 2 for chip select 0 for frequency set 1.
  [7:0] PI_MR1_DATA_F1_0 — Data to program into memory mode register 1 for chip select 0 for frequency set 1.
0x2458 DDRSS_PI_278
  [31:24] PI_MR23_DATA_F1_0 — Data to program into memory mode register 23 for chip select 0 for frequency set 1.
  [23:16] PI_MR22_DATA_F1_0 — Data to program into memory mode register 22 for chip select 0 for frequency set 1.
  [15:8] PI_MR14_DATA_F1_0 — Data to program into memory mode register 14 for chip select 0 for frequency set 1.
  [7:0] PI_MR12_DATA_F1_0 — Data to program into memory mode register 12 for chip select 0 for frequency set 1.
0x245C DDRSS_PI_279
  [31:24] PI_MR11_DATA_F2_0 — Data to program into memory mode register 11 for chip select 0 for frequency set 2.
  [23:16] PI_MR3_DATA_F2_0 — Data to program into memory mode register 3 for chip select 0 for frequency set 2.
  [15:8] PI_MR2_DATA_F2_0 — Data to program into memory mode register 2 for chip select 0 for frequency set 2.
  [7:0] PI_MR1_DATA_F2_0 — Data to program into memory mode register 1 for chip select 0 for frequency set 2.
0x2460 DDRSS_PI_280
  [31:24] PI_MR23_DATA_F2_0 — Data to program into memory mode register 23 for chip select 0 for frequency set 2.
  [23:16] PI_MR22_DATA_F2_0 — Data to program into memory mode register 22 for chip select 0 for frequency set 2.
  [15:8] PI_MR14_DATA_F2_0 — Data to program into memory mode register 14 for chip select 0 for frequency set 2.
  [7:0] PI_MR12_DATA_F2_0 — Data to program into memory mode register 12 for chip select 0 for frequency set 2.
0x2464 DDRSS_PI_281
  [31:24] PI_MR11_DATA_F0_1 — Data to program into memory mode register 11 for chip select 1 for frequency set 0.
  [23:16] PI_MR3_DATA_F0_1 — Data to program into memory mode register 3 for chip select 1 for frequency set 0.
  [15:8] PI_MR2_DATA_F0_1 — Data to program into memory mode register 2 for chip select 1 for frequency set 0.
  [7:0] PI_MR1_DATA_F0_1 — Data to program into memory mode register 1 for chip select 1 for frequency set 0.
0x2468 DDRSS_PI_282
  [31:24] PI_MR23_DATA_F0_1 — Data to program into memory mode register 23 for chip select 1 for frequency set 0.
  [23:16] PI_MR22_DATA_F0_1 — Data to program into memory mode register 22 for chip select 1 for frequency set 0.
  [15:8] PI_MR14_DATA_F0_1 — Data to program into memory mode register 14 for chip select 1 for frequency set 0.
  [7:0] PI_MR12_DATA_F0_1 — Data to program into memory mode register 12 for chip select 1 for frequency set 0.
0x246C DDRSS_PI_283
  [31:24] PI_MR11_DATA_F1_1 — Data to program into memory mode register 11 for chip select 1 for frequency set 1.
  [23:16] PI_MR3_DATA_F1_1 — Data to program into memory mode register 3 for chip select 1 for frequency set 1.
  [15:8] PI_MR2_DATA_F1_1 — Data to program into memory mode register 2 for chip select 1 for frequency set 1.
  [7:0] PI_MR1_DATA_F1_1 — Data to program into memory mode register 1 for chip select 1 for frequency set 1.
0x2470 DDRSS_PI_284
  [31:24] PI_MR23_DATA_F1_1 — Data to program into memory mode register 23 for chip select 1 for frequency set 1.
  [23:16] PI_MR22_DATA_F1_1 — Data to program into memory mode register 22 for chip select 1 for frequency set 1.
  [15:8] PI_MR14_DATA_F1_1 — Data to program into memory mode register 14 for chip select 1 for frequency set 1.
  [7:0] PI_MR12_DATA_F1_1 — Data to program into memory mode register 12 for chip select 1 for frequency set 1.
0x2474 DDRSS_PI_285
  [31:24] PI_MR11_DATA_F2_1 — Data to program into memory mode register 11 for chip select 1 for frequency set 2.
  [23:16] PI_MR3_DATA_F2_1 — Data to program into memory mode register 3 for chip select 1 for frequency set 2.
  [15:8] PI_MR2_DATA_F2_1 — Data to program into memory mode register 2 for chip select 1 for frequency set 2.
  [7:0] PI_MR1_DATA_F2_1 — Data to program into memory mode register 1 for chip select 1 for frequency set 2.
0x2478 DDRSS_PI_286
  [31:24] PI_MR23_DATA_F2_1 — Data to program into memory mode register 23 for chip select 1 for frequency set 2.
  [23:16] PI_MR22_DATA_F2_1 — Data to program into memory mode register 22 for chip select 1 for frequency set 2.
  [15:8] PI_MR14_DATA_F2_1 — Data to program into memory mode register 14 for chip select 1 for frequency set 2.
  [7:0] PI_MR12_DATA_F2_1 — Data to program into memory mode register 12 for chip select 1 for frequency set 2.
0x247C DDRSS_PI_287
  [31:24] PI_MR11_DATA_F0_2 — Data to program into memory mode register 11 for chip select 2 for frequency set 0.
  [23:16] PI_MR3_DATA_F0_2 — Data to program into memory mode register 3 for chip select 2 for frequency set 0.
  [15:8] PI_MR2_DATA_F0_2 — Data to program into memory mode register 2 for chip select 2 for frequency set 0.
  [7:0] PI_MR1_DATA_F0_2 — Data to program into memory mode register 1 for chip select 2 for frequency set 0.
0x2480 DDRSS_PI_288
  [31:24] PI_MR23_DATA_F0_2 — Data to program into memory mode register 23 for chip select 2 for frequency set 0.
  [23:16] PI_MR22_DATA_F0_2 — Data to program into memory mode register 22 for chip select 2 for frequency set 0.
  [15:8] PI_MR14_DATA_F0_2 — Data to program into memory mode register 14 for chip select 2 for frequency set 0.
  [7:0] PI_MR12_DATA_F0_2 — Data to program into memory mode register 12 for chip select 2 for frequency set 0.
0x2484 DDRSS_PI_289
  [31:24] PI_MR11_DATA_F1_2 — Data to program into memory mode register 11 for chip select 2 for frequency set 1.
  [23:16] PI_MR3_DATA_F1_2 — Data to program into memory mode register 3 for chip select 2 for frequency set 1.
  [15:8] PI_MR2_DATA_F1_2 — Data to program into memory mode register 2 for chip select 2 for frequency set 1.
  [7:0] PI_MR1_DATA_F1_2 — Data to program into memory mode register 1 for chip select 2 for frequency set 1.
0x2488 DDRSS_PI_290
  [31:24] PI_MR23_DATA_F1_2 — Data to program into memory mode register 23 for chip select 2 for frequency set 1.
  [23:16] PI_MR22_DATA_F1_2 — Data to program into memory mode register 22 for chip select 2 for frequency set 1.
  [15:8] PI_MR14_DATA_F1_2 — Data to program into memory mode register 14 for chip select 2 for frequency set 1.
  [7:0] PI_MR12_DATA_F1_2 — Data to program into memory mode register 12 for chip select 2 for frequency set 1.
0x248C DDRSS_PI_291
  [31:24] PI_MR11_DATA_F2_2 — Data to program into memory mode register 11 for chip select 2 for frequency set 2.
  [23:16] PI_MR3_DATA_F2_2 — Data to program into memory mode register 3 for chip select 2 for frequency set 2.
  [15:8] PI_MR2_DATA_F2_2 — Data to program into memory mode register 2 for chip select 2 for frequency set 2.
  [7:0] PI_MR1_DATA_F2_2 — Data to program into memory mode register 1 for chip select 2 for frequency set 2.
0x2490 DDRSS_PI_292
  [31:24] PI_MR23_DATA_F2_2 — Data to program into memory mode register 23 for chip select 2 for frequency set 2.
  [23:16] PI_MR22_DATA_F2_2 — Data to program into memory mode register 22 for chip select 2 for frequency set 2.
  [15:8] PI_MR14_DATA_F2_2 — Data to program into memory mode register 14 for chip select 2 for frequency set 2.
  [7:0] PI_MR12_DATA_F2_2 — Data to program into memory mode register 12 for chip select 2 for frequency set 2.
0x2494 DDRSS_PI_293
  [31:24] PI_MR11_DATA_F0_3 — Data to program into memory mode register 11 for chip select 3 for frequency set 0.
  [23:16] PI_MR3_DATA_F0_3 — Data to program into memory mode register 3 for chip select 3 for frequency set 0.
  [15:8] PI_MR2_DATA_F0_3 — Data to program into memory mode register 2 for chip select 3 for frequency set 0.
  [7:0] PI_MR1_DATA_F0_3 — Data to program into memory mode register 1 for chip select 3 for frequency set 0.
0x2498 DDRSS_PI_294
  [31:24] PI_MR23_DATA_F0_3 — Data to program into memory mode register 23 for chip select 3 for frequency set 0.
  [23:16] PI_MR22_DATA_F0_3 — Data to program into memory mode register 22 for chip select 3 for frequency set 0.
  [15:8] PI_MR14_DATA_F0_3 — Data to program into memory mode register 14 for chip select 3 for frequency set 0.
  [7:0] PI_MR12_DATA_F0_3 — Data to program into memory mode register 12 for chip select 3 for frequency set 0.
0x249C DDRSS_PI_295
  [31:24] PI_MR11_DATA_F1_3 — Data to program into memory mode register 11 for chip select 3 for frequency set 1.
  [23:16] PI_MR3_DATA_F1_3 — Data to program into memory mode register 3 for chip select 3 for frequency set 1.
  [15:8] PI_MR2_DATA_F1_3 — Data to program into memory mode register 2 for chip select 3 for frequency set 1.
  [7:0] PI_MR1_DATA_F1_3 — Data to program into memory mode register 1 for chip select 3 for frequency set 1.
0x24A0 DDRSS_PI_296
  [31:24] PI_MR23_DATA_F1_3 — Data to program into memory mode register 23 for chip select 3 for frequency set 1.
  [23:16] PI_MR22_DATA_F1_3 — Data to program into memory mode register 22 for chip select 3 for frequency set 1.
  [15:8] PI_MR14_DATA_F1_3 — Data to program into memory mode register 14 for chip select 3 for frequency set 1.
  [7:0] PI_MR12_DATA_F1_3 — Data to program into memory mode register 12 for chip select 3 for frequency set 1.
0x24A4 DDRSS_PI_297
  [31:24] PI_MR11_DATA_F2_3 — Data to program into memory mode register 11 for chip select 3 for frequency set 2.
  [23:16] PI_MR3_DATA_F2_3 — Data to program into memory mode register 3 for chip select 3 for frequency set 2.
  [15:8] PI_MR2_DATA_F2_3 — Data to program into memory mode register 2 for chip select 3 for frequency set 2.
  [7:0] PI_MR1_DATA_F2_3 — Data to program into memory mode register 1 for chip select 3 for frequency set 2.
0x24A8 DDRSS_PI_298
  [31:24] PI_MR23_DATA_F2_3 — Data to program into memory mode register 23 for chip select 3 for frequency set 2.
  [23:16] PI_MR22_DATA_F2_3 — Data to program into memory mode register 22 for chip select 3 for frequency set 2.
  [15:8] PI_MR14_DATA_F2_3 — Data to program into memory mode register 14 for chip select 3 for frequency set 2.
  [7:0] PI_MR12_DATA_F2_3 — Data to program into memory mode register 12 for chip select 3 for frequency set 2.
0x24AC DDRSS_PI_299
  [10:0] PI_PARITY_ERROR_REGIF — Inject parity error to regisster interface signals for PI.
